# CY8C5888LTI_LP097 register map
File version: 0.1
CY8C58LP
Registers are 8-bit, read-write, no defined reset value unless marked. A register's access mark holds for its fields unless they carry their own. Offsets are from the block's base; lines under a group give offsets from that group; [hi:lo] are bit positions; {n}, {i} and the like mark numbered series; 'fields as' and 'values as' point back to an identical list; <NAME> marks a mode.

## Memory map
0x00000000 SPI_Slave
0x00000000 PWM_M4
0x00000000 PWM_M3
0x00000000 PWM_M1
0x00000000 UART_1 — UART
0x00000000 PWM_M2

## SPI_Slave
Base 0x00000000
0x40006407 SPI_Slave_RX_DATA — SPIS RX Data
0x40006407 SPI_Slave_TX_DATA — SPIS TX Data
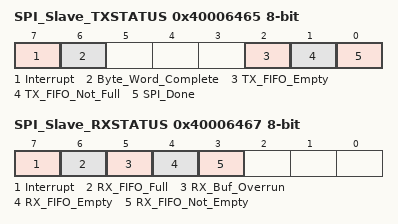
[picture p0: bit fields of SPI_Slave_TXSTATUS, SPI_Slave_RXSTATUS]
0x40006465 SPI_Slave_TXSTATUS — SPIS TX Status Register
  [7] Interrupt ro — Set when interrupt occurs
  [6] Byte_Word_Complete ro — Set when a byte/word transmit has completed
  [2] TX_FIFO_Empty ro — Set when the TX Data FIFO is empty
  [1] TX_FIFO_Not_Full ro — Set when the TX Data FIFO is not full
  [0] SPI_Done ro — Set when all of the data in the transmit FIFO has been sent. Set when Byte/Word Complete has been set and TX Data FIFO is empty
0x40006467 SPI_Slave_RXSTATUS — SPIS RX Status Register
  [7] Interrupt ro — Set when interrupt occurs
  [6] RX_FIFO_Full ro — Set when the RX Data FIFO is full
  [5] RX_Buf_Overrun ro — Set when RX Data has overrun the 4 byte/word FIFO without being moved to the RX buffer cmemory array (if one exists)
  [4] RX_FIFO_Empty ro — Set when the RX Data FIFO is empty
  [3] RX_FIFO_Not_Empty ro — Set when the RX Data FIFO is not empty. That is, at least one byte/word is in the RX FIFO

## PWM_M4
Base 0x00000000
0x4000642D PWM_M4_COMPARE_Reg_ — UDB.D0 - Assigned Compare Value
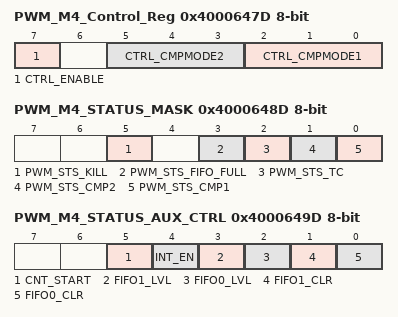
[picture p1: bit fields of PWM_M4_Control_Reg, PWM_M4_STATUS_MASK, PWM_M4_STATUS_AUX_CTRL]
0x4000647D PWM_M4_Control_Reg — UDB Control Register - Assigned Control Register Value
  [7] CTRL_ENABLE — Enable the PWM
  [5:3] CTRL_CMPMODE2 — Compare mode 2
  [2:0] CTRL_CMPMODE1 — Compare mode 1
0x4000648D PWM_M4_STATUS_MASK — UDB Status bits Interrupt Mask Enable Register
  [5] PWM_STS_KILL ro — Enables the Interrupt on Kill
  [3] PWM_STS_FIFO_FULL ro — FIFO Full Status Mask
  [2] PWM_STS_TC ro — Enables the Interrupt on Terminal Count
  [1] PWM_STS_CMP2 ro — Enables the Interrupt on Compare 2
  [0] PWM_STS_CMP1 ro — Enables the Interrupt on Compare 1
0x4000649D PWM_M4_STATUS_AUX_CTRL — UDB Auxilliary Control Register
  [5] CNT_START — FIFO0 clear
    0=E_CNT_START0 (Disable counter); 1=E_CNT_START1 (Enable counter)
  [4] INT_EN
    0=E_INT_EN0 (Interrupt disabled); 1=E_INT_EN1 (Interrupt enabled)
  [3] FIFO1_LVL — FIFO level
    0=E_FIFO_LVL_0 (FIFO LVL: input mode: FIFO not full; output mode: FIFO not empty); 1=E_FIFO_LVL_1 (FIFO LVL: input mode: FIFO at least 1/2 empty; output mode: FIFO at least 1/2 full)
  [2] FIFO0_LVL — FIFO level
    values as FIFO1_LVL
  [1] FIFO1_CLR — FIFO1 clear
    0=E_FIFO_CLR_0 (Normal FIFO operation); 1=E_FIFO_CLR_1 (Clear FIFO state)
  [0] FIFO0_CLR — FIFO0 clear
    values as FIFO1_CLR

## PWM_M3
Base 0x00000000
0x40006422 PWM_M3_COMPARE_Reg_ — UDB.D0 - Assigned Compare Value
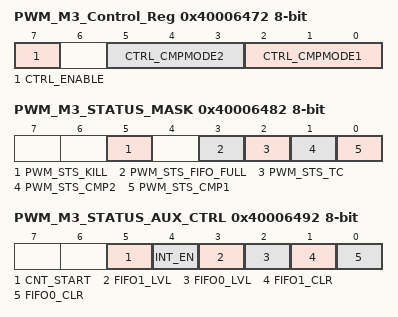
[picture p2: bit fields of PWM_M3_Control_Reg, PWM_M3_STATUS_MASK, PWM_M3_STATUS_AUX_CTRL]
0x40006472 PWM_M3_Control_Reg — UDB Control Register - Assigned Control Register Value
  [7] CTRL_ENABLE — Enable the PWM
  [5:3] CTRL_CMPMODE2 — Compare mode 2
  [2:0] CTRL_CMPMODE1 — Compare mode 1
0x40006482 PWM_M3_STATUS_MASK — UDB Status bits Interrupt Mask Enable Register
  fields as PWM_M4.PWM_M4_STATUS_MASK
0x40006492 PWM_M3_STATUS_AUX_CTRL — UDB Auxilliary Control Register
  fields as PWM_M4.PWM_M4_STATUS_AUX_CTRL

## PWM_M1
Base 0x00000000
0x4000642C PWM_M1_COMPARE_Reg_ — UDB.D0 - Assigned Compare Value
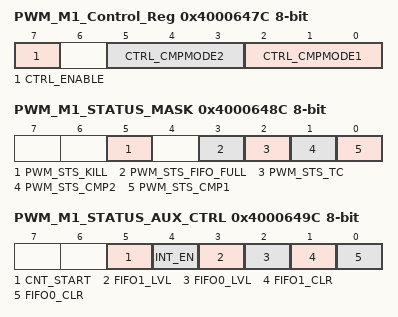
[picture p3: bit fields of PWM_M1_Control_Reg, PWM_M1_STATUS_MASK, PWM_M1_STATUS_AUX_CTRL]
0x4000647C PWM_M1_Control_Reg — UDB Control Register - Assigned Control Register Value
  [7] CTRL_ENABLE — Enable the PWM
  [5:3] CTRL_CMPMODE2 — Compare mode 2
  [2:0] CTRL_CMPMODE1 — Compare mode 1
0x4000648C PWM_M1_STATUS_MASK — UDB Status bits Interrupt Mask Enable Register
  fields as PWM_M4.PWM_M4_STATUS_MASK
0x4000649C PWM_M1_STATUS_AUX_CTRL — UDB Auxilliary Control Register
  fields as PWM_M4.PWM_M4_STATUS_AUX_CTRL

## UART_1 — UART
Base 0x00000000
0x40006445 TX_UART_1_TX_DATA — TX Data Register
0x40006524 RX_UART_1_RX_ADDRESS1 — RX Address1 Register
0x40006534 RX_UART_1_RX_ADDRESS2 — RX Address2 Register
0x40006544 RX_UART_1_RX_DATA — RX Data Register
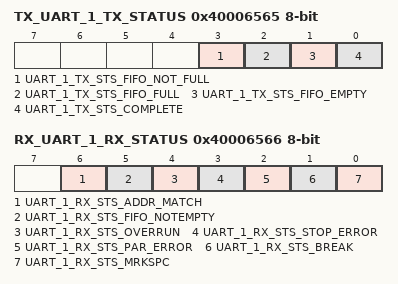
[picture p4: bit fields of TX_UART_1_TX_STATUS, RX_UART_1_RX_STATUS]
0x40006565 TX_UART_1_TX_STATUS — TX status register
  [3] UART_1_TX_STS_FIFO_NOT_FULL ro, [2] UART_1_TX_STS_FIFO_FULL ro, [1] UART_1_TX_STS_FIFO_EMPTY ro, [0] UART_1_TX_STS_COMPLETE ro
0x40006566 RX_UART_1_RX_STATUS — RX status register
  [6] UART_1_RX_STS_ADDR_MATCH ro, [5] UART_1_RX_STS_FIFO_NOTEMPTY ro, [4] UART_1_RX_STS_OVERRUN ro, [3] UART_1_RX_STS_STOP_ERROR ro, [2] UART_1_RX_STS_PAR_ERROR ro, [1] UART_1_RX_STS_BREAK ro, [0] UART_1_RX_STS_MRKSPC ro

## PWM_M2
Base 0x00000000
0x40006423 PWM_M2_COMPARE_Reg_ — UDB.D0 - Assigned Compare Value
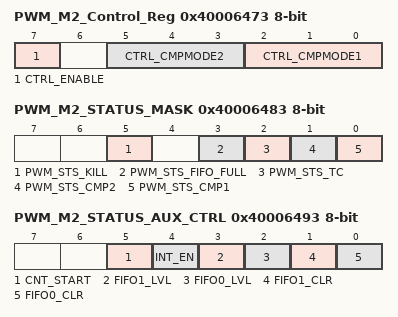
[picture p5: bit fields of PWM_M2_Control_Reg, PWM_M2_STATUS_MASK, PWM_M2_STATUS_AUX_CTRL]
0x40006473 PWM_M2_Control_Reg — UDB Control Register - Assigned Control Register Value
  [7] CTRL_ENABLE — Enable the PWM
  [5:3] CTRL_CMPMODE2 — Compare mode 2
  [2:0] CTRL_CMPMODE1 — Compare mode 1
0x40006483 PWM_M2_STATUS_MASK — UDB Status bits Interrupt Mask Enable Register
  fields as PWM_M4.PWM_M4_STATUS_MASK
0x40006493 PWM_M2_STATUS_AUX_CTRL — UDB Auxilliary Control Register
  fields as PWM_M4.PWM_M4_STATUS_AUX_CTRL
